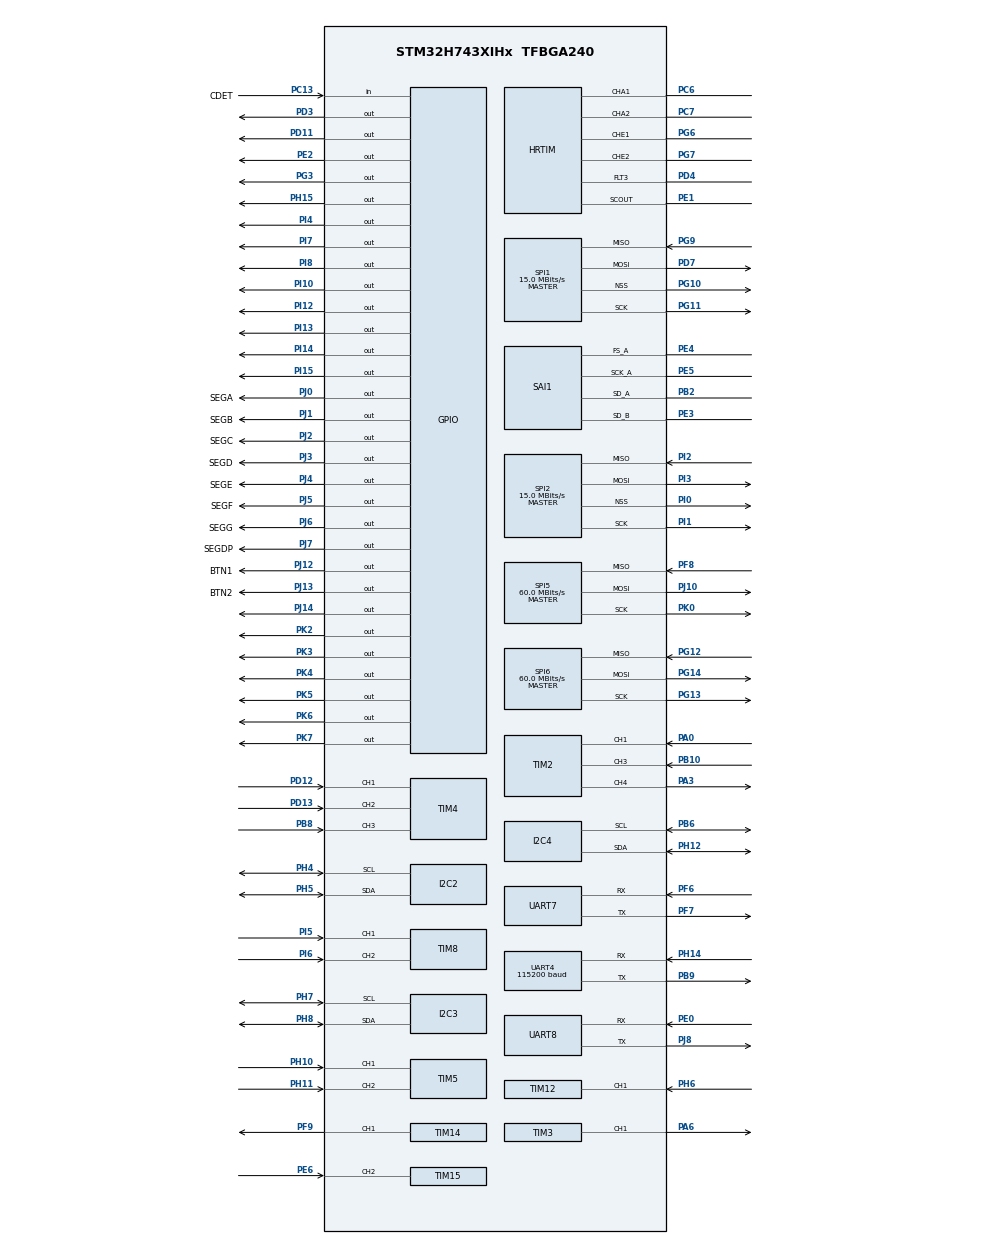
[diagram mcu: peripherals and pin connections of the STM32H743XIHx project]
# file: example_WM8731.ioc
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SPI6.Mode=SPI_MODE_MASTER
PD7.Mode=Full_Duplex_Master
PK5.Signal=GPIO_Output
Dma.SAI1_A.1.SignalID=NONE
SAI1.VirtualMode-SAI_A_AsyncSlave=VM_SLAVE
VP_TIM17_VS_ClockSourceINT.Mode=Enable_Timer
PH12.Signal=I2C4_SDA
SAI1.ClockStrobing-SAI_B_SyncSlave=SAI_CLOCKSTROBING_FALLINGEDGE
TIM4.Channel-Input_Capture3_from_TI3=TIM_CHANNEL_3
SPI1.VirtualType=VM_MASTER
SPI2.VirtualType=VM_MASTER
PK0.Mode=Full_Duplex_Master
Dma.SAI1_B.0.MemInc=DMA_MINC_ENABLE
Dma.SAI1_A.1.SyncSignalID=NONE
RCC.PLLFRACN=0
VP_RTC_VS_RTC_Activate.Mode=RTC_Enabled
PJ6.GPIO_Label=SEGG
Dma.SAI1_A.1.Mode=DMA_CIRCULAR
PA15\ (JTDI).Signal=DEBUG_JTDI
SAI1.FSOffset-SAI_A_AsyncSlave=SAI_FS_FIRSTBIT
Dma.SAI1_A.1.MemDataAlignment=DMA_MDATAALIGN_HALFWORD
PG13.Signal=SPI6_SCK
PG6.Mode=Output_TE1TE2
RCC.SYSCLKSource=RCC_SYSCLKSOURCE_PLLCLK
PJ10.Signal=SPI5_MOSI
PA14\ (JTCK/SWCLK).Signal=DEBUG_JTCK-SWCLK
PA15\ (JTDI).Mode=JTAG_5_pins
PJ13.GPIO_Label=BTN2
PH5.Signal=I2C2_SDA
PF7.Signal=UART7_TX
SH.S_TIM14_CH1.0=TIM14_CH1,PWM Generation1 CH1
I2C4.Timing=0x307075B1
SPI1.Direction=SPI_DIRECTION_2LINES
Dma.SAI1_A.1.Instance=DMA1_Stream1
PD4.Signal=HRTIM_FLT3
PB6.Signal=I2C4_SCL
TIM2.Channel-Input_Capture3_from_TI3=TIM_CHANNEL_3
PC7.Signal=HRTIM_CHA2
PB6.Mode=I2C
SPI1.CalculateBaudRate=15.0 MBits/s
PE5.Signal=SAI1_SCK_A
Dma.SAI1_A.1.FIFOMode=DMA_FIFOMODE_DISABLE
PE1.Signal=HRTIM_SCOUT
PI3.Mode=Full_Duplex_Master
SH.ADCx_INN1.0=ADC2_INN1
SH.ADCx_INN1.1=ADC1_INN1
Dma.SAI1_A.1.MemInc=DMA_MINC_ENABLE
PB2.Signal=SAI1_SD_A
RCC.DIVM2=1
RCC.DIVM1=1
PG14.Mode=Full_Duplex_Master
Dma.SAI1_B.0.PeriphInc=DMA_PINC_DISABLE
SH.S_TIM12_CH1.0=TIM12_CH1,PWM_Input_1
SAI1.SlotNumber-SAI_A_AsyncSlave=2
PI6.Signal=S_TIM8_CH2
PI3.Signal=SPI2_MOSI
SPI2.CalculateBaudRate=15.0 MBits/s
SH.S_TIM4_CH2.0=TIM4_CH2,Encoder_Interface
PE2.Signal=GPIO_Output
PF8.Mode=Full_Duplex_Master
PA14\ (JTCK/SWCLK).Mode=JTAG_5_pins
SPI1.VirtualNSS=VM_NSSHARD
VP_TIM1_VS_ClockSourceINT.Mode=Internal
PA0.Signal=S_TIM2_CH1
PJ14.Signal=GPIO_Output
Mcu.Package=TFBGA240
PB9.Signal=UART4_TX
PH12.Mode=I2C
SAI1.SlotActive-SAI_B_SyncSlave=0x0000FFFF
SPI2.Mode=SPI_MODE_MASTER
Dma.SAI1_A.1.Direction=DMA_PERIPH_TO_MEMORY
PD12.Signal=S_TIM4_CH1
SAI1.FSPolarity-SAI_B_SyncSlave=SAI_FS_ACTIVE_HIGH
PJ4.Signal=GPIO_Output
SPI5.CalculateBaudRate=60.0 MBits/s
PC14-OSC32_IN\ (OSC32_IN).Mode=LSE-External-Oscillator
Dma.SAI1_B.0.FIFOMode=DMA_FIFOMODE_DISABLE
SH.S_TIM4_CH1.0=TIM4_CH1,Encoder_Interface
PD4.Mode=Fault_Enable3
RCC.APB4Freq_Value=120000000
RCC.FDCANCLockSelection=RCC_FDCANCLKSOURCE_PLL2
TIM1.Period=10-1
VP_TIM14_VS_ClockSourceINT.Mode=Enable_Timer
PH8.Mode=I2C
PH0-OSC_IN\ (PH0).Mode=HSE-External-Oscillator
SPI5.VirtualType=VM_MASTER
PJ1.GPIO_Label=SEGB
PG12.Signal=SPI6_MISO
PK4.Signal=GPIO_Output
PH15.Signal=GPIO_Output
Dma.SAI1_B.0.PeriphDataAlignment=DMA_PDATAALIGN_HALFWORD
SAI1.DataSize-SAI_B_SyncSlave=SAI_DATASIZE_16
PG9.Signal=SPI1_MISO
PC13.Signal=GPIO_Input
PD3.Signal=GPIO_Output
PE1.Mode=SCOUTmode
PG9.Mode=Full_Duplex_Master
PC6.Signal=HRTIM_CHA1
PD7.Signal=SPI1_MOSI
PI12.Signal=GPIO_Output
RCC.DIVP2=1
VP_TIM16_VS_ClockSourceINT.Mode=Enable_Timer
Dma.SAI1_B.0.SignalID=NONE
PI2.Mode=Full_Duplex_Master
SH.S_TIM8_CH2.0=TIM8_CH2,Encoder_Interface
Dma.SAI1_B.0.EventEnable=DISABLE
PG10.Signal=SPI1_NSS
Dma.SAI1_B.0.Priority=DMA_PRIORITY_LOW
Dma.SAI1_A.1.Polarity=HAL_DMAMUX_REQ_GEN_RISING
PJ7.Signal=GPIO_Output
PJ3.Signal=GPIO_Output
SPI6.CalculateBaudRate=60.0 MBits/s
PC6.Mode=Output_TA1TA2
RCC.DIVN2=9
RCC.DIVN1=60
PB10.Signal=S_TIM2_CH3
RCC.USBCLockSelection=RCC_USBCLKSOURCE_HSI48
SH.S_TIM8_CH1.0=TIM8_CH1,Encoder_Interface
PJ4.GPIO_Label=SEGE
PH14.Mode=Asynchronous
PI7.Signal=GPIO_Output
TIM1.TIM_MasterOutputTrigger=TIM_TRGO_UPDATE
VP_TIM13_VS_ClockSourceINT.Mode=Enable_Timer
TIM14.Channel=TIM_CHANNEL_1
SAI1.SlotNumber-SAI_B_SyncSlave=2
SPI1.Mode=SPI_MODE_MASTER
SAI1.TriState-SAI_A_AsyncSlave=SAI_OUTPUT_RELEASED
PI2.Signal=SPI2_MISO
PI1.Signal=SPI2_SCK
Dma.SAI1_A.1.EventEnable=DISABLE
PB4\ (NJTRST).Mode=JTAG_5_pins
PH4.Mode=I2C
PD11.Signal=GPIO_Output
SAI1.AudioMode-SAI_A_AsyncSlave=SAI_MODESLAVE_RX
Dma.SAI1_A.1.SyncRequestNumber=1
PG11.Mode=Full_Duplex_Master
PJ0.GPIO_Label=SEGA
PJ8.Signal=UART8_TX
ProjectManager.HeapSize=0x200
PH6.Signal=S_TIM12_CH1
PF6.Mode=Asynchronous
PF9.Signal=S_TIM14_CH1
PJ10.Mode=Full_Duplex_Master
NVIC.PriorityGroup=NVIC_PRIORITYGROUP_4
PB3\ (JTDO/TRACESWO).Mode=JTAG_5_pins
Dma.SAI1_A.1.Priority=DMA_PRIORITY_LOW
PE3.Signal=SAI1_SD_B
Dma.SAI1_A.1.PeriphInc=DMA_PINC_DISABLE
PA13\ (JTMS/SWDIO).Signal=DEBUG_JTMS-SWDIO
SPI6.VirtualType=VM_MASTER
Mcu.Family=STM32H7
PK7.Signal=GPIO_Output
PK3.Signal=GPIO_Output
SPI2.VirtualNSS=VM_NSSHARD
RCC.CortexFreq_Value=480000000
TIM2.Channel-Input_Capture1_from_TI1=TIM_CHANNEL_1
PG6.Signal=HRTIM_CHE1
PH14.Signal=UART4_RX
PH10.Signal=S_TIM5_CH1
RCC.HPRE=RCC_HCLK_DIV2
SAI1.FSPolarity-SAI_A_AsyncSlave=SAI_FS_ACTIVE_HIGH
PH0-OSC_IN\ (PH0).Signal=RCC_OSC_IN
SAI1.FrameLength-SAI_A_AsyncSlave=32
Dma.SAI1_B.0.SyncPolarity=HAL_DMAMUX_SYNC_NO_EVENT
PC15-OSC32_OUT\ (OSC32_OUT).Mode=LSE-External-Oscillator
SAI1.FrameLength-SAI_B_SyncSlave=32
TIM4.EncoderMode=TIM_ENCODERMODE_TI1
PA1_C.Signal=ADCx_INP1
Dma.SAI1_B.0.Polarity=HAL_DMAMUX_REQ_GEN_RISING
I2C2.Timing=0x307075B1
SH.S_TIM5_CH2.0=TIM5_CH2,Encoder_Interface
NVIC.TIM1_UP_IRQn=true\:0\:0\:false\:false\:true\:true\:true
RCC.PLL2FRACN=3072
PC13.GPIO_Label=CDET
PG11.Signal=SPI1_SCK
PJ5.GPIO_Label=SEGF
ProjectManager.StackSize=0x400
SH.S_TIM15_CH2.0=TIM15_CH2,Input_Capture2_from_TI2
Dma.SAI1_A.1.RequestNumber=1
SAI1.Instance-SAI_A_AsyncSlave=SAI$Index_Block_A
VP_TIM7_VS_ClockSourceINT.Mode=Enable_Timer
PD13.Signal=S_TIM4_CH2
PJ6.Signal=GPIO_Output
TIM1.Prescaler=600-1
PJ2.Signal=GPIO_Output
SAI1.VirtualMode-SAI_B_SyncSlave=VM_SLAVE
SAI1.VirtualSlotActive-SAI_A_AsyncSlave=SAI_SLOTACTIVE_ALL
UART4.BaudRate=115200
RCC.HCLKFreq_Value=240000000
PI13.Signal=GPIO_Output
SPI2.BaudRatePrescaler=SPI_BAUDRATEPRESCALER_32
TIM3.Channel-PWM\ Generation1\ CH1=TIM_CHANNEL_1
Dma.SAI1_B.0.SyncRequestNumber=1
PH1-OSC_OUT\ (PH1).Mode=HSE-External-Oscillator
RCC.HSE_VALUE=16000000
PI8.Signal=GPIO_Output
PI5.Signal=S_TIM8_CH1
PI0.Signal=SPI2_NSS
PJ7.GPIO_Label=SEGDP
PC13.GPIO_PuPd=GPIO_PULLUP
PJ12.GPIO_Label=BTN1
PG13.Mode=Full_Duplex_Master
PE4.Mode=SAI_A_AsyncSlave
SH.S_TIM3_CH1.0=TIM3_CH1,PWM Generation1 CH1
PE4.Signal=SAI1_FS_A
PH7.Mode=I2C
RCC.APB3Freq_Value=120000000
SAI1.VirtualSlotActive-SAI_B_SyncSlave=SAI_SLOTACTIVE_ALL
PA6.Signal=S_TIM3_CH1
RCC.D1PPRE=RCC_APB3_DIV2
PJ12.Signal=GPIO_Output
SAI1.DataSize-SAI_A_AsyncSlave=SAI_DATASIZE_16
PF8.Signal=SPI5_MISO
PJ1.Signal=GPIO_Output
PI1.Mode=Full_Duplex_Master
Dma.SAI1_B.0.Mode=DMA_CIRCULAR
PH7.Signal=I2C3_SCL
I2C3.Timing=0x307075B1
SAI1.SlotActive-SAI_A_AsyncSlave=0x0000FFFF
PJ3.GPIO_Label=SEGD
Dma.Request1=SAI1_A
SH.S_TIM5_CH1.0=TIM5_CH1,Encoder_Interface
Dma.SAI1_B.0.Instance=DMA1_Stream0
NVIC.DMA1_Stream0_IRQn=true\:0\:0\:false\:false\:true\:false\:true
SPI2.Direction=SPI_DIRECTION_2LINES
Dma.SAI1_A.1.SyncPolarity=HAL_DMAMUX_SYNC_NO_EVENT
Dma.SAI1_A.1.SyncEnable=DISABLE
Dma.Request0=SAI1_B
SPI1.BaudRatePrescaler=SPI_BAUDRATEPRESCALER_32
PE3.Mode=SAI_B_SyncSlave
PA3.Signal=S_TIM2_CH4
RCC.PLLSourceVirtual=RCC_PLLSOURCE_HSE
PK6.Signal=GPIO_Output
Dma.SAI1_B.0.MemDataAlignment=DMA_MDATAALIGN_HALFWORD
TIM2.Channel-PWM\ Generation4\ CH4=TIM_CHANNEL_4
PK2.Signal=GPIO_Output
SH.S_TIM2_CH1.0=TIM2_CH1,Input_Capture1_from_TI1
CORTEX_M7.CPU_ICache=Disabled
PG7.Signal=HRTIM_CHE2
PA13\ (JTMS/SWDIO).Mode=JTAG_5_pins
PA0_C.Signal=ADCx_INN1
PJ8.Mode=Asynchronous
PH11.Signal=S_TIM5_CH2
PG3.Signal=GPIO_Output
PI14.Signal=GPIO_Output
PG10.Mode=NSS_Signal_Hard_Output
VP_TIM6_VS_ClockSourceINT.Mode=Enable_Timer
TIM15.Channel-Input_Capture2_from_TI2=TIM_CHANNEL_2
RCC.D2PPRE2=RCC_APB2_DIV2
RCC.D2PPRE1=RCC_APB1_DIV2
PI10.Signal=GPIO_Output
NVIC.DMA1_Stream1_IRQn=true\:0\:0\:false\:false\:true\:false\:true
SPI5.Mode=SPI_MODE_MASTER
PH1-OSC_OUT\ (PH1).Signal=RCC_OSC_OUT
SH.ADCx_INP1.1=ADC1_INP1
SH.ADCx_INP1.0=ADC2_INP1
PF7.Mode=Asynchronous
CORTEX_M7.MPU_Control=__NULL
PH4.Signal=I2C2_SCL
PF6.Signal=UART7_RX
PB3\ (JTDO/TRACESWO).Signal=DEBUG_JTDO-SWO
ProjectManager.TargetToolchain=Makefile
PC15-OSC32_OUT\ (OSC32_OUT).Signal=RCC_OSC32_OUT
PH8.Signal=I2C3_SDA
SH.S_TIM4_CH3.0=TIM4_CH3,Input_Capture3_from_TI3
PI0.Mode=NSS_Signal_Hard_Output
PB9.Mode=Asynchronous
Dma.SAI1_B.0.Direction=DMA_MEMORY_TO_PERIPH
RCC.USBFreq_Value=48000000
PG7.Mode=Output_TE1TE2
PK0.Signal=SPI5_SCK
SAI1.AudioMode-SAI_B_SyncSlave=SAI_MODESLAVE_TX
Dma.SAI1_B.0.SyncEnable=DISABLE
PG14.Signal=SPI6_MOSI
board=custom
PG12.Mode=Full_Duplex_Master
RCC.APB2Freq_Value=120000000
SH.S_TIM2_CH3.0=TIM2_CH3,Input_Capture3_from_TI3
PI4.Signal=GPIO_Output
PE5.Mode=SAI_A_AsyncSlave
RCC.ADCFreq_Value=150000000
SPI6.Direction=SPI_DIRECTION_2LINES
Dma.SAI1_B.0.SyncSignalID=NONE
SAI1.ClockStrobing-SAI_A_AsyncSlave=SAI_CLOCKSTROBING_FALLINGEDGE
PE6.Signal=S_TIM15_CH2
PJ0.Signal=GPIO_Output
Mcu.Name=STM32H743XIHx
PE0.Signal=UART8_RX
RCC.SYSCLKFreq_VALUE=480000000
PC14-OSC32_IN\ (OSC32_IN).Signal=RCC_OSC32_IN
PB2.Mode=SAI_A_AsyncSlave
PJ5.Signal=GPIO_Output
SAI1.Instance-SAI_B_SyncSlave=SAI$Index_Block_B
SH.S_TIM2_CH4.0=TIM2_CH4,PWM Generation4 CH4
SAI1.FSOffset-SAI_B_SyncSlave=SAI_FS_FIRSTBIT
PI15.Signal=GPIO_Output
Dma.SAI1_A.1.PeriphDataAlignment=DMA_PDATAALIGN_HALFWORD
PB8.Signal=S_TIM4_CH3
RCC.D3PPRE=RCC_APB4_DIV2
PH5.Mode=I2C
CORTEX_M7.CPU_DCache=Disabled
PC7.Mode=Output_TA1TA2
RCC.APB1Freq_Value=120000000
PJ2.GPIO_Label=SEGC
SAI1.TriState-SAI_B_SyncSlave=SAI_OUTPUT_NOTRELEASED
Dma.SAI1_B.0.RequestNumber=1
PE0.Mode=Asynchronous
PJ13.Signal=GPIO_Output
SPI5.Direction=SPI_DIRECTION_2LINES
PB4\ (NJTRST).Signal=DEBUG_JTRST

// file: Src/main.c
/* USER CODE BEGIN Header */
/**
  ******************************************************************************
  * @file           : main.c
  * @brief          : Main program body
  ******************************************************************************
  * @attention
  *
  * <h2><center>&copy; Copyright (c) 2020 STMicroelectronics.
  * All rights reserved.</center></h2>
  *
  * This software component is licensed by ST under BSD 3-Clause license,
  * the "License"; You may not use this file except in compliance with the
  * License. You may obtain a copy of the License at:
  *                        opensource.org/licenses/BSD-3-Clause
  *
  ******************************************************************************
  */
/* USER CODE END Header */
#include "main.h"
#include "dma.h"
#include "hrtim.h"
#include "i2c.h"
#include "rtc.h"
#include "sai.h"
#include "spi.h"
#include "tim.h"
#include "usart.h"
#include "gpio.h"

/* USER CODE BEGIN Includes */
#include "i2c_hal.h"
#include "wm8731.h"
/* USER CODE END Includes */

void SystemClock_Config(void);

int main(void)
{

  /* MCU Configuration--------------------------------------------------------*/

  /* Reset of all peripherals, Initializes the Flash interface and the Systick. */
  HAL_Init();

  /* Configure the system clock */
  SystemClock_Config();

  /* Initialize all configured peripherals */
  MX_GPIO_Init();
  MX_DMA_Init();
  MX_HRTIM_Init();
  MX_I2C2_Init();
  MX_I2C3_Init();
  MX_I2C4_Init();
  MX_UART4_Init();
  MX_UART7_Init();
  MX_UART8_Init();
  MX_RTC_Init();
  MX_SAI1_Init();
  MX_SPI1_Init();
  MX_SPI2_Init();
  MX_SPI5_Init();
  MX_SPI6_Init();
  MX_TIM1_Init();
  MX_TIM2_Init();
  MX_TIM3_Init();
  MX_TIM4_Init();
  MX_TIM5_Init();
  MX_TIM6_Init();
  MX_TIM7_Init();
  MX_TIM8_Init();
  MX_TIM12_Init();
  MX_TIM13_Init();
  MX_TIM14_Init();
  MX_TIM15_Init();
  MX_TIM16_Init();
  MX_TIM17_Init();
  /* USER CODE BEGIN 2 */
  struct i2c_dev_s i2c_dev;
  i2c_init(&i2c_dev, &hi2c2);

  int16_t dac_buffer[WM8731_DAC_BUF_LEN/2],  adc_buffer[WM8731_DAC_BUF_LEN/2];
  struct wm8731_dev_s wm8731_dev;
  wm8731_init(&wm8731_dev, &i2c_dev, &hsai_BlockB1, &hsai_BlockA1, 0b00110100);
  wm8731_dev.setup(&wm8731_dev, ADC48_DAC48); //initialize audio codec and set sampling rate
  wm8731_dev.startAdcDma(&wm8731_dev); //start audio input
  wm8731_dev.startDacDma(&wm8731_dev); //start audio output
  /* USER CODE END 2 */

  /* Infinite loop */
  /* USER CODE BEGIN WHILE */
  while (1)
  {
    wm8731_dev.waitInBuf(&wm8731_dev);
    wm8731_dev.getInBuf(&wm8731_dev, adc_buffer);
    for(int16_t cnt=0; cnt<WM8731_DAC_BUF_LEN/2; cnt++)
    {
      dac_buffer[cnt] = adc_buffer[cnt];  // passthrough, but could do more interesting stuff here
    }
    wm8731_dev.waitOutBuf(&wm8731_dev);
    wm8731_dev.putOutBuf(&wm8731_dev, dac_buffer);
    /* USER CODE END WHILE */

  }
}

void SystemClock_Config(void)
{
  RCC_OscInitTypeDef RCC_OscInitStruct = {0};
  RCC_ClkInitTypeDef RCC_ClkInitStruct = {0};
  RCC_PeriphCLKInitTypeDef PeriphClkInitStruct = {0};

  /** Supply configuration update enable
  */
  HAL_PWREx_ConfigSupply(PWR_LDO_SUPPLY);
  /** Configure the main internal regulator output voltage
  */
  __HAL_PWR_VOLTAGESCALING_CONFIG(PWR_REGULATOR_VOLTAGE_SCALE0);

  while(!__HAL_PWR_GET_FLAG(PWR_FLAG_VOSRDY)) {}
  /** Initializes the RCC Oscillators according to the specified parameters
  * in the RCC_OscInitTypeDef structure.
  */
  RCC_OscInitStruct.OscillatorType = RCC_OSCILLATORTYPE_LSI|RCC_OSCILLATORTYPE_HSE;
  RCC_OscInitStruct.HSEState = RCC_HSE_ON;
  RCC_OscInitStruct.LSIState = RCC_LSI_ON;
  RCC_OscInitStruct.PLL.PLLState = RCC_PLL_ON;
  RCC_OscInitStruct.PLL.PLLSource = RCC_PLLSOURCE_HSE;
  RCC_OscInitStruct.PLL.PLLM = 1;
  RCC_OscInitStruct.PLL.PLLN = 60;
  RCC_OscInitStruct.PLL.PLLP = 2;
  RCC_OscInitStruct.PLL.PLLQ = 2;
  RCC_OscInitStruct.PLL.PLLR = 2;
  RCC_OscInitStruct.PLL.PLLRGE = RCC_PLL1VCIRANGE_3;
  RCC_OscInitStruct.PLL.PLLVCOSEL = RCC_PLL1VCOWIDE;
  RCC_OscInitStruct.PLL.PLLFRACN = 0;
  if (HAL_RCC_OscConfig(&RCC_OscInitStruct) != HAL_OK)
  {
    Error_Handler();
  }
  /** Initializes the CPU, AHB and APB buses clocks
  */
  RCC_ClkInitStruct.ClockType = RCC_CLOCKTYPE_HCLK|RCC_CLOCKTYPE_SYSCLK
                              |RCC_CLOCKTYPE_PCLK1|RCC_CLOCKTYPE_PCLK2
                              |RCC_CLOCKTYPE_D3PCLK1|RCC_CLOCKTYPE_D1PCLK1;
  RCC_ClkInitStruct.SYSCLKSource = RCC_SYSCLKSOURCE_PLLCLK;
  RCC_ClkInitStruct.SYSCLKDivider = RCC_SYSCLK_DIV1;
  RCC_ClkInitStruct.AHBCLKDivider = RCC_HCLK_DIV2;
  RCC_ClkInitStruct.APB3CLKDivider = RCC_APB3_DIV2;
  RCC_ClkInitStruct.APB1CLKDivider = RCC_APB1_DIV2;
  RCC_ClkInitStruct.APB2CLKDivider = RCC_APB2_DIV2;
  RCC_ClkInitStruct.APB4CLKDivider = RCC_APB4_DIV2;

  if (HAL_RCC_ClockConfig(&RCC_ClkInitStruct, FLASH_LATENCY_4) != HAL_OK)
  {
    Error_Handler();
  }
  PeriphClkInitStruct.PeriphClockSelection = RCC_PERIPHCLK_RTC|RCC_PERIPHCLK_HRTIM1
                              |RCC_PERIPHCLK_UART4|RCC_PERIPHCLK_UART7
                              |RCC_PERIPHCLK_UART8|RCC_PERIPHCLK_SPI5
                              |RCC_PERIPHCLK_SPI1|RCC_PERIPHCLK_SPI2
                              |RCC_PERIPHCLK_SAI1|RCC_PERIPHCLK_I2C2
                              |RCC_PERIPHCLK_I2C3|RCC_PERIPHCLK_SPI6
                              |RCC_PERIPHCLK_I2C4;
  PeriphClkInitStruct.Sai1ClockSelection = RCC_SAI1CLKSOURCE_PLL;
  PeriphClkInitStruct.Spi123ClockSelection = RCC_SPI123CLKSOURCE_PLL;
  PeriphClkInitStruct.Spi45ClockSelection = RCC_SPI45CLKSOURCE_D2PCLK1;
  PeriphClkInitStruct.Usart234578ClockSelection = RCC_USART234578CLKSOURCE_D2PCLK1;
  PeriphClkInitStruct.I2c123ClockSelection = RCC_I2C123CLKSOURCE_D2PCLK1;
  PeriphClkInitStruct.I2c4ClockSelection = RCC_I2C4CLKSOURCE_D3PCLK1;
  PeriphClkInitStruct.Spi6ClockSelection = RCC_SPI6CLKSOURCE_D3PCLK1;
  PeriphClkInitStruct.RTCClockSelection = RCC_RTCCLKSOURCE_LSI;
  PeriphClkInitStruct.Hrtim1ClockSelection = RCC_HRTIM1CLK_TIMCLK;
  if (HAL_RCCEx_PeriphCLKConfig(&PeriphClkInitStruct) != HAL_OK)
  {
    Error_Handler();
  }
}

void Error_Handler(void)
{
}

/************************ (C) COPYRIGHT STMicroelectronics *****END OF FILE****/
